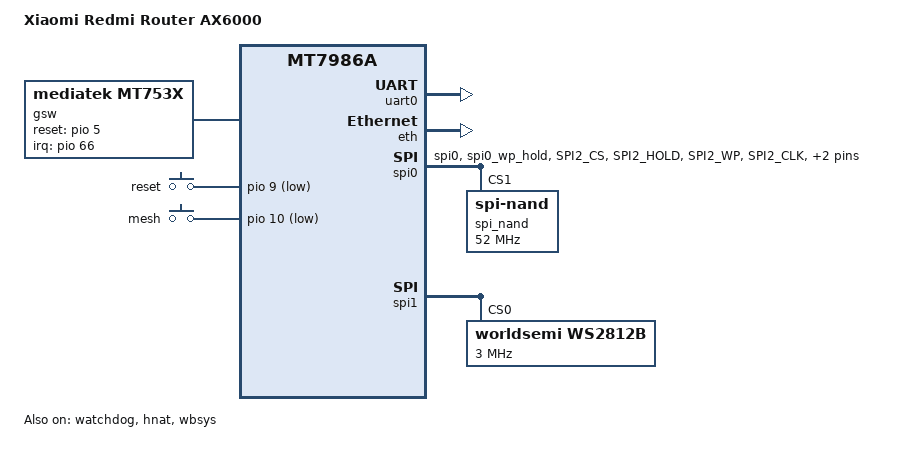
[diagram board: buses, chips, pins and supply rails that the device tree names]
/dts-v1/;
#include <dt-bindings/input/input.h>
#include <dt-bindings/gpio/gpio.h>
#include <dt-bindings/leds/common.h>

#include "mt7986a.dtsi"
#include "mt7986a-pinctrl.dtsi"

/ {
	model = "Xiaomi Redmi Router AX6000";
	compatible = "xiaomi,redmi-router-ax6000", "mediatek,mt7986a";

	aliases {
		serial0 = &uart0;
		led-boot = &led_status_rgb;
		led-failsafe = &led_status_rgb;
		led-running = &led_status_rgb;
		led-upgrade = &led_status_rgb;
	};

	chosen {
		bootargs = "console=ttyS0,115200n1 loglevel=8 \
			    earlycon=uart8250,mmio32,0x11002000";
	};

	gsw: gsw@0 {
		compatible = "mediatek,mt753x";
		mediatek,ethsys = <&ethsys>;
		#address-cells = <1>;
		#size-cells = <0>;
	};

	keys {
		compatible = "gpio-keys";

		reset {
			label = "reset";
			gpios = <&pio 9 GPIO_ACTIVE_LOW>;
			linux,code = <KEY_RESTART>;
		};

		mesh {
			label = "mesh";
			gpios = <&pio 10 GPIO_ACTIVE_LOW>;
			linux,code = <BTN_9>;
			linux,input-type = <EV_SW>;
		};
	};

	nmbm_spim_nand {
		compatible = "generic,nmbm";
		#address-cells = <1>;
		#size-cells = <1>;

		lower-mtd-device = <&spi_nand>;
		forced-create;

		partitions {
			compatible = "fixed-partitions";
			#address-cells = <1>;
			#size-cells = <1>;

			partition@0 {
				label = "BL2";
				reg = <0x000000 0x100000>;
			};

			partition@100000 {
				label = "Nvram";
				reg = <0x100000 0x40000>;
			};

			partition@140000 {
				label = "Bdata";
				reg = <0x140000 0x40000>;
			};

			factory: partition@180000 {
				label = "Factory";
				reg = <0x180000 0x200000>;
			};

			partition@380000 {
				label = "FIP";
				reg = <0x380000 0x200000>;
			};

			partition@580000 {
				label = "ubi";
				reg = <0x580000 0x7280000>;
			};
		};
	};
};

&uart0 {
	status = "okay";
};

&watchdog {
	status = "okay";
};

&eth {
	status = "okay";

	gmac0: mac@0 {
		compatible = "mediatek,eth-mac";
		reg = <0>;
		phy-mode = "2500base-x";

		fixed-link {
			speed = <2500>;
			full-duplex;
			pause;
		};
	};

	gmac1: mac@1 {
		compatible = "mediatek,eth-mac";
		reg = <1>;
		phy-mode = "2500base-x";

		fixed-link {
			speed = <2500>;
			full-duplex;
			pause;
		};
	};

	mdio: mdio-bus {
		#address-cells = <1>;
		#size-cells = <0>;
	};
};

&gsw {
	compatible = "mediatek,mt753x";
	#address-cells = <1>;
    #size-cells = <0>;
	mediatek,mdio = <&mdio>;
	mediatek,portmap = "llllw";
	mediatek,mdio_master_pinmux = <0>;
	reset-gpios = <&pio 5 0>;
	interrupt-parent = <&pio>;
	interrupts = <66 IRQ_TYPE_LEVEL_HIGH>;
	status = "okay";

	port5: port@5 {
		compatible = "mediatek,mt753x-port";
		reg = <5>;
		phy-mode = "2500base-x";

		fixed-link {
			speed = <2500>;
			full-duplex;
		};
	};

	port6: port@6 {
		compatible = "mediatek,mt753x-port";
		mediatek,ssc-on;
		reg = <6>;
		phy-mode = "2500base-x";

		fixed-link {
			speed = <2500>;
			full-duplex;
		};
	};
};

&hnat {
	mtketh-wan = "eth1";
	mtketh-lan = "eth0";
	mtketh-max-gmac = <2>;
	mtketh-ppe-num = <2>;
	status = "okay";
};

&spi0 {
	pinctrl-names = "default";
	pinctrl-0 = <&spi_flash_pins>;
	cs-gpios = <0>, <0>;
	status = "okay";

	spi_nand: spi_nand@1 {
		#address-cells = <1>;
		#size-cells = <1>;
		compatible = "spi-nand";
		reg = <1>;
		spi-max-frequency = <52000000>;
		spi-tx-bus-width = <4>;
		spi-rx-bus-width = <4>;
		spi-cal-enable;
		spi-cal-mode = "read-data";
		spi-cal-datalen = <7>;
		spi-cal-data = /bits/ 8 <0x53 0x50 0x49 0x4E 0x41 0x4E 0x44>; /* 'SPINAND' */
		spi-cal-addrlen = <5>;
		spi-cal-addr = /bits/ 32 <0x0 0x0 0x0 0x0 0x0>;
	};
};

&spi1 {
	pinctrl-names = "default";
	pinctrl-0 = <&spic_pins_g2>;
	status = "okay";

	ws2812b@0 {
		#address-cells = <1>;
		#size-cells = <0>;
		compatible = "worldsemi,ws2812b";
		reg = <0>;
		spi-max-frequency = <3000000>;

		led_status_rgb: led@0 {
			reg = <0>;
			label = "rgb:status";
			color-index = <LED_COLOR_ID_RED LED_COLOR_ID_GREEN LED_COLOR_ID_BLUE>;
		};

		led_network_rgb: led@1 {
			reg = <1>;
			label = "rgb:network";
			color-index = <LED_COLOR_ID_RED LED_COLOR_ID_GREEN LED_COLOR_ID_BLUE>;
		};
	};
};

&wbsys {
	mediatek,mtd-eeprom = <&factory 0x0000>;
	status = "okay";
};

&pio {
	spi_flash_pins: spi-flash-pins-33-to-38 {
		mux {
			function = "flash";
			groups = "spi0", "spi0_wp_hold";
		};
		conf-pu {
			pins = "SPI2_CS", "SPI2_HOLD", "SPI2_WP";
			drive-strength = <8>;
			mediatek,pull-up-adv = <0>;
		};
		conf-pd {
			pins = "SPI2_CLK", "SPI2_MOSI", "SPI2_MISO";
			drive-strength = <8>;
			mediatek,pull-down-adv = <0>;
		};
	};
};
